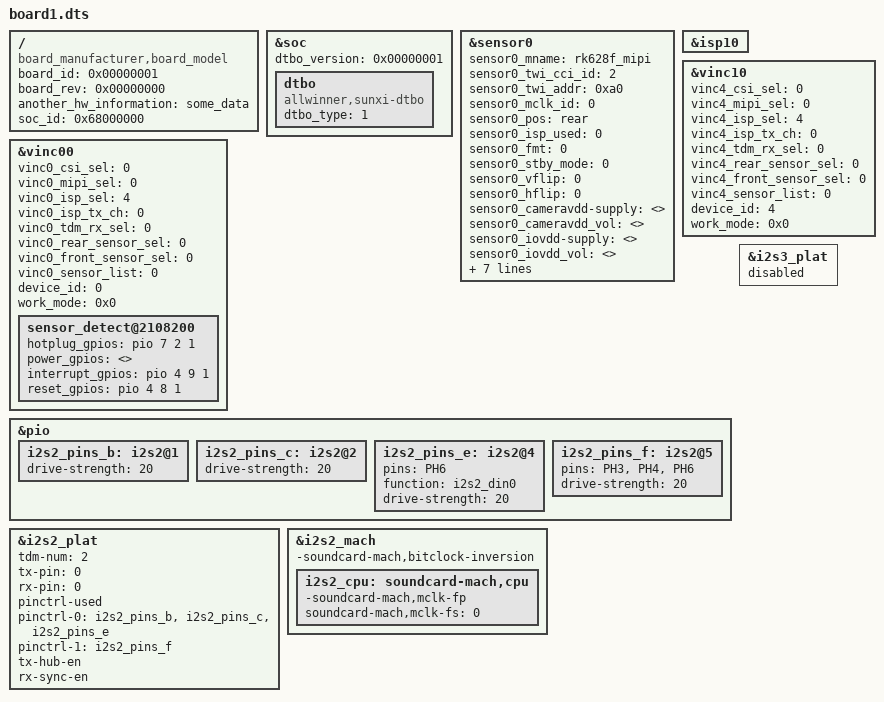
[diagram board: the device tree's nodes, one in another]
/dts-v1/;
/plugin/;
/ {
  /* As DTS design, these properties only for loader, won't overlay */
  compatible = "board_manufacturer,board_model";

  /* These properties are examples */
  board_id = <0x00000001>;
  board_rev = <0x00000000>;
  another_hw_information = "some_data";
  soc_id = <0x68000000>;

};

&soc {
	dtbo_version = <0x00000001>;
	dtbo{
		compatible = "allwinner,sunxi-dtbo";
		dtbo_type = <1>;
	};
};



&sensor0 {
	device_type = "sensor0";
	sensor0_mname = "rk628f_mipi";
	sensor0_twi_cci_id = <2>;
	sensor0_twi_addr = <0xa0>;
	sensor0_mclk_id = <0>;
	sensor0_pos = "rear";
	sensor0_isp_used = <0>;
	sensor0_fmt = <0>;
	sensor0_stby_mode = <0>;
	sensor0_vflip = <0>;
	sensor0_hflip = <0>;
	sensor0_cameravdd-supply = <>;
	sensor0_cameravdd_vol = <>;
	sensor0_iovdd-supply = <>;
	sensor0_iovdd_vol = <>;
	sensor0_avdd-supply = <>;
	sensor0_avdd_vol = <>;
	sensor0_dvdd-supply = <>;
	sensor0_dvdd_vol = <>;
	sensor0_power_en = <>;
	sensor0_reset = <>;
	sensor0_pwdn = <>;
	status = "okay";
};

&vinc00 {
	vinc0_csi_sel = <0>;
	vinc0_mipi_sel = <0>;
	vinc0_isp_sel = <4>;
	vinc0_isp_tx_ch = <0>;
	vinc0_tdm_rx_sel = <0>;
	vinc0_rear_sensor_sel = <0>;
	vinc0_front_sensor_sel = <0>;
	vinc0_sensor_list = <0>;
	device_id = <0>;
	work_mode = <0x0>;
	status = "okay";
	sensor_detect@2108200 {
		hotplug_gpios = <&pio 7 2 1>;		/* <&pio PH 2 GPIO_ACTIVE_HIGH> */
		power_gpios = <>;
		interrupt_gpios = <&pio 4 9 1>;		/* <&pio PE 9 GPIO_ACTIVE_LOW> */
		reset_gpios = <&pio 4 8 1>;		/* <&pio PE 8 GPIO_ACTIVE_LOW> */
	};
};

&isp10 {
	status = "okay";
};
&vinc10 {
	vinc4_csi_sel = <0>;
	vinc4_mipi_sel = <0>;
	vinc4_isp_sel = <4>;
	vinc4_isp_tx_ch = <0>;
	vinc4_tdm_rx_sel = <0>;
	vinc4_rear_sensor_sel = <0>;
	vinc4_front_sensor_sel = <0>;
	vinc4_sensor_list = <0>;
	device_id = <4>;
	work_mode = <0x0>;
	status = "okay";
};
/* i2s2 pins */
&pio {
	/* i2s2 pins */
	i2s2_pins_b: i2s2@1 {
		drive-strength = <20>;
	};

	i2s2_pins_c: i2s2@2 {
		drive-strength = <20>;
	};

	i2s2_pins_e: i2s2@4 {
		pins = "PH6";
		function = "i2s2_din0";
		drive-strength = <20>;
	};

	i2s2_pins_f: i2s2@5 {
		pins = "PH3", "PH4", "PH6";
		drive-strength = <20>;
	};

};
&i2s2_plat {
	tdm-num		= <2>;
	tx-pin		= <0>;
	rx-pin		= <0>;
	pinctrl-used;
	pinctrl-names= "default","sleep";
	pinctrl-0	= <&i2s2_pins_b &i2s2_pins_c &i2s2_pins_e>;
	pinctrl-1	= <&i2s2_pins_f>;
	tx-hub-en;
	rx-sync-en;
	status		= "okay";
};
/*
&i2s2_plat {
	pinctrl-0	= <&i2s2_pins_b &i2s2_pins_c &i2s2_pins_e>;
	status		= "okay";
};
*/
/* hdmi in */


&i2s3_plat {
	status		= "disabled";
};
&i2s2_mach {
	/* soundcard-mach,frame-inversion; */
	/* soundcard-mach,bitclock-inversion; */
	-soundcard-mach,bitclock-inversion;
	status		= "okay";
	i2s2_cpu: soundcard-mach,cpu {
		-soundcard-mach,mclk-fp;
		soundcard-mach,mclk-fs	= <0>;
	};
};

